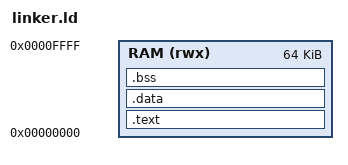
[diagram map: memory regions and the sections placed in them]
ENTRY(_start)

MEMORY
{
    RAM (rwx) : ORIGIN = 0x00000000, LENGTH = 64K
}

SECTIONS
{
    .text :
    {
        KEEP(*(.text.start))
        *(.text*)
        *(.rodata*)
    } > RAM

    .data :
    {
        *(.data*)
    } > RAM

    .bss (NOLOAD) :
    {
        __bss_start = .;
        *(.bss*)
        *(COMMON)
        __bss_end = .;
    } > RAM

    . = ALIGN(16);
    _end = .;
    _stack_top = ORIGIN(RAM) + LENGTH(RAM);
}

